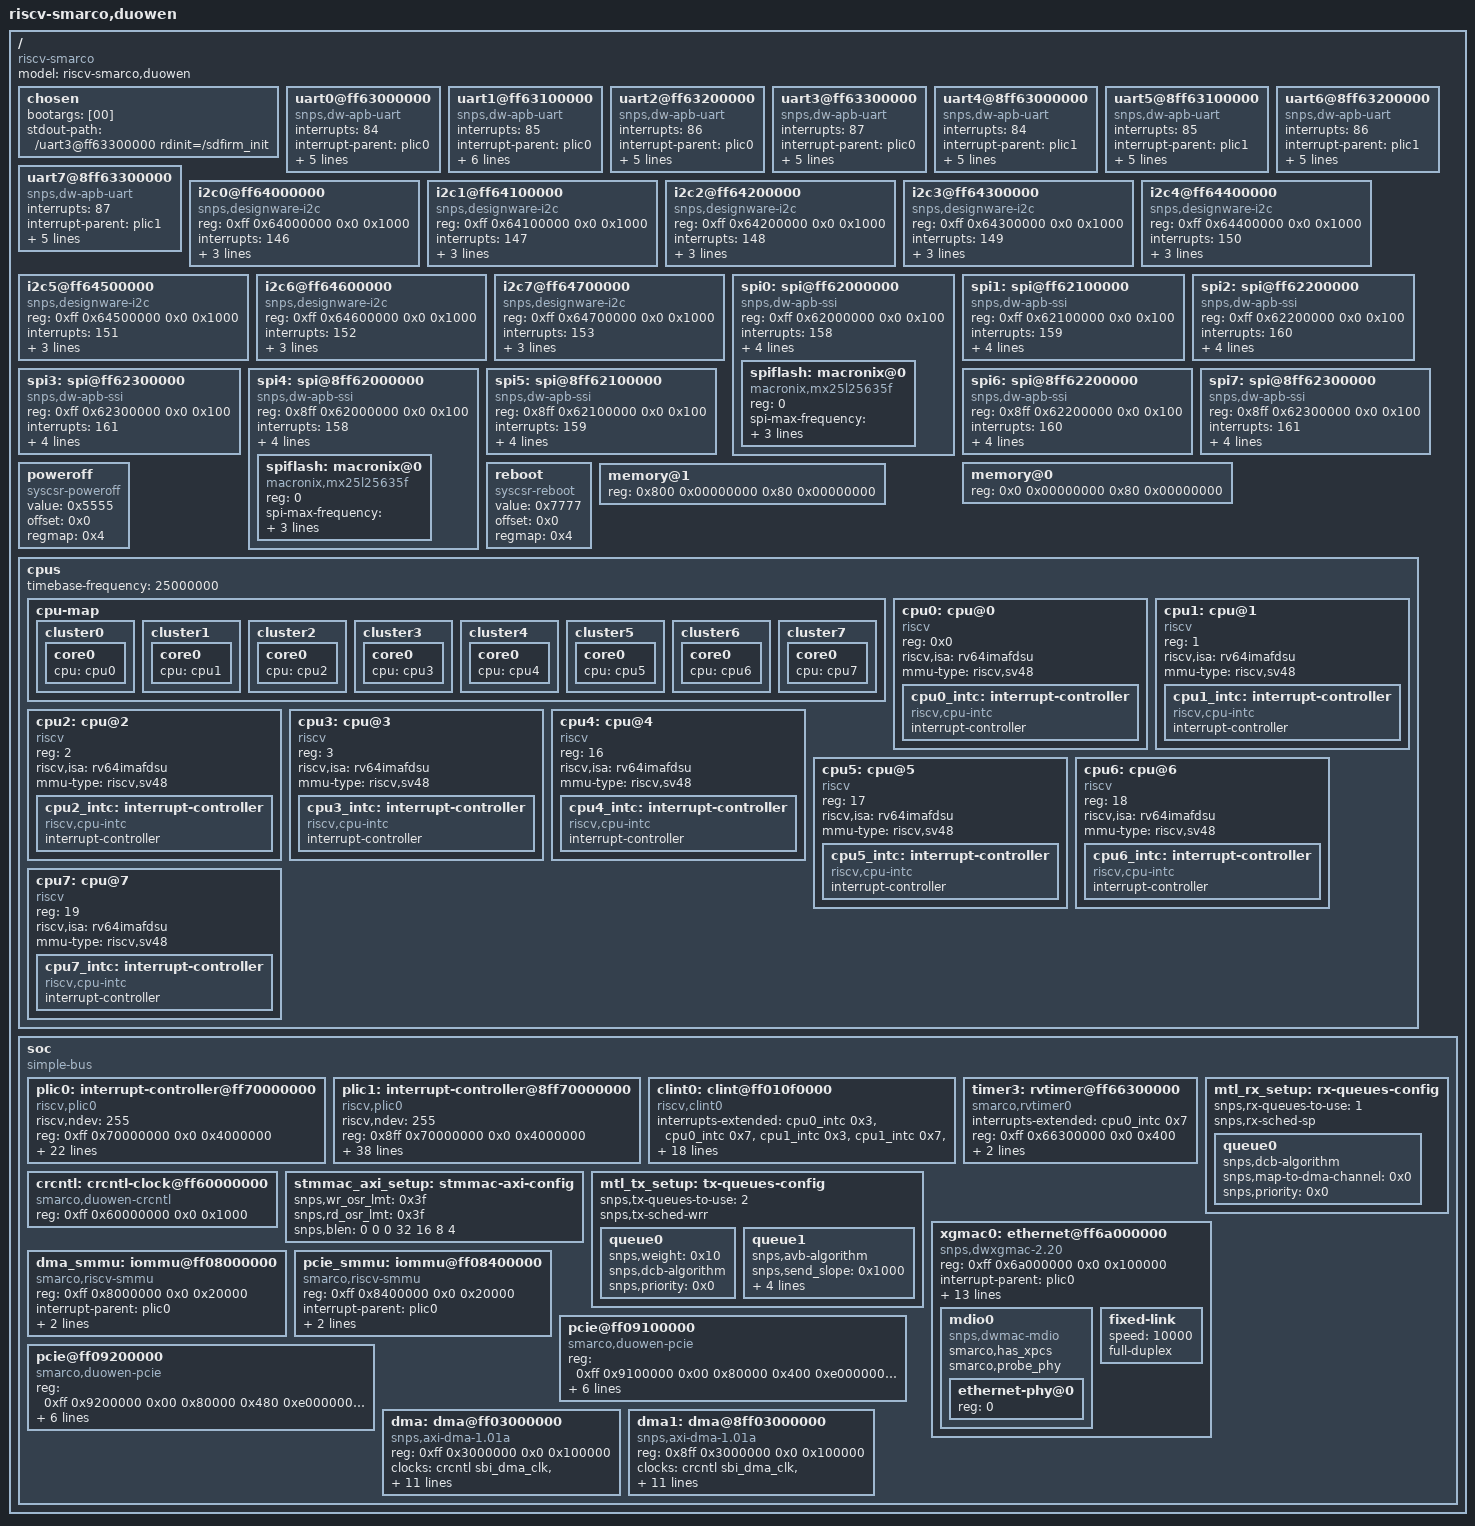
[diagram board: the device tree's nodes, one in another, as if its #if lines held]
/* SPDX-License-Identifier: GPL-2.0-or-later */
/*
 *  Copyright (C) 2021 CAS SmartCore Co., Ltd.
 *    Author: 2021 Lv Zheng <zhenglv@smarco.cn>
 */

#include <target/config.h>
#include <dt-bindings/clock/sbi-clock-duowen.h>

/dts-v1/;

/ {
	#address-cells = <0x2>;
	#size-cells = <0x2>;
	compatible = "riscv-smarco";
	model = "riscv-smarco,duowen";

	chosen {
#ifdef CONFIG_DUOWEN_UART_DTS_CON
		bootargs = [00];
#ifdef CONFIG_DUOWEN_UART_CON0
		stdout-path = "/uart0@ff63000000 rdinit=/sdfirm_init";
#endif /* CONFIG_DUOWEN_UART_CON0 */
#ifdef CONFIG_DUOWEN_UART_CON1
		stdout-path = "/uart1@ff63100000 rdinit=/sdfirm_init";
#endif /* CONFIG_DUOWEN_UART_CON1 */
#ifdef CONFIG_DUOWEN_UART_CON2
		stdout-path = "/uart2@ff63200000 rdinit=/sdfirm_init";
#endif /* CONFIG_DUOWEN_UART_CON2 */
#ifdef CONFIG_DUOWEN_UART_CON3
		stdout-path = "/uart3@ff63300000 rdinit=/sdfirm_init";
#endif /* CONFIG_DUOWEN_UART_CON3 */
#else /* CONFIG_DUOWEN_UART_DTS_CON */
		bootargs = "console=hvc0 earlycon=sbi rdinit=/sdfirm_init";
#endif /* CONFIG_DUOWEN_UART_DTS_CON */
	};

#ifdef CONFIG_DUOWEN_UART_DTS
	uart0@ff63000000 {
		interrupts = <84>;
		interrupt-parent = <&plic0>;
#ifdef CONFIG_DUOWEN_UART_DTS_CLK_FREQ
		clock-frequency = <APB_CLK_FREQ>;
#else
		clocks = <&crcntl sbi_uart0_clk>, <&crcntl sbi_uart0_clk>;
		clock-names = "baudclk", "apb_pclk";
#endif
		reg = <0xff 0x63000000 0x0 0x100>;
		reg-io-width = <4>;
		reg-shift = <2>;
		compatible = "snps,dw-apb-uart";
#ifdef CONFIG_DUOWEN_UART_CON0
#ifdef CONFIG_DUOWEN_UART_DTS_CON
		status = "okay";
		current-speed = <UART_CURRENT_SPEED>;
#else /* CONFIG_DUOWEN_UART_DTS_CON */
		status = "disabled";
#endif /* CONFIG_DUOWEN_UART_DTS_CON */
#else /* CONFIG_DUOWEN_UART_CON0 */
		status = "okay";
#endif /* CONFIG_DUOWEN_UART_CON0 */
	};
	uart1@ff63100000 {
		interrupts = <85>;
		interrupt-parent = <&plic0>;
#ifdef CONFIG_DUOWEN_UART_DTS_CLK_FREQ
		clock-frequency = <APB_CLK_FREQ>;
#else
		clocks = <&crcntl sbi_uart1_clk>, <&crcntl sbi_uart1_clk>;
		clock-names = "baudclk", "apb_pclk";
#endif
		reg = <0xff 0x63100000 0x0 0x100>;
		reg-io-width = <4>;
		reg-shift = <2>;
		compatible = "snps,dw-apb-uart";
#ifdef CONFIG_DUOWEN_UART_DTS_DMA
		dmas = <&dma 0>, <&dma 1>;
		dma-names = "tx", "rx";
#endif /* CONFIG_DUOWEN_UART_DTS_DMA */
#ifdef CONFIG_DUOWEN_UART_CON1
#ifdef CONFIG_DUOWEN_UART_DTS_CON
		status = "okay";
		current-speed = <UART_CURRENT_SPEED>;
#else /* CONFIG_DUOWEN_UART_DTS_CON */
		status = "disabled";
#endif /* CONFIG_DUOWEN_UART_DTS_CON */
#else /* CONFIG_DUOWEN_UART_CON1 */
		status = "okay";
#endif /* CONFIG_DUOWEN_UART_CON1 */
	};
	uart2@ff63200000 {
		interrupts = <86>;
		interrupt-parent = <&plic0>;
#ifdef CONFIG_DUOWEN_UART_DTS_CLK_FREQ
		clock-frequency = <APB_CLK_FREQ>;
#else /* CONFIG_DUOWEN_UART_DTS_CLK_FREQ */
		clocks = <&crcntl sbi_uart2_clk>, <&crcntl sbi_uart2_clk>;
		clock-names = "baudclk", "apb_pclk";
#endif /* CONFIG_DUOWEN_UART_DTS_CLK_FREQ */
		reg = <0xff 0x63200000 0x0 0x100>;
		reg-io-width = <4>;
		reg-shift = <2>;
		compatible = "snps,dw-apb-uart";
#ifdef CONFIG_DUOWEN_UART_CON2
#ifdef CONFIG_DUOWEN_UART_DTS_CON
		status = "okay";
		current-speed = <UART_CURRENT_SPEED>;
#else /* CONFIG_DUOWEN_UART_DTS_CON */
		status = "disabled";
#endif /* CONFIG_DUOWEN_UART_DTS_CON */
#else /* CONFIG_DUOWEN_UART_CON2 */
		status = "okay";
#endif /* CONFIG_DUOWEN_UART_CON2 */
	};
	uart3@ff63300000 {
		interrupts = <87>;
		interrupt-parent = <&plic0>;
#ifdef CONFIG_DUOWEN_UART_DTS_CLK_FREQ
		clock-frequency = <APB_CLK_FREQ>;
#else /* CONFIG_DUOWEN_UART_DTS_CLK_FREQ */
		clocks = <&crcntl sbi_uart3_clk>, <&crcntl sbi_uart3_clk>;
		clock-names = "baudclk", "apb_pclk";
#endif /* CONFIG_DUOWEN_UART_DTS_CLK_FREQ */
		reg = <0xff 0x63300000 0x0 0x100>;
		reg-io-width = <4>;
		reg-shift = <2>;
		compatible = "snps,dw-apb-uart";
#ifdef CONFIG_DUOWEN_UART_CON3
#ifdef CONFIG_DUOWEN_UART_DTS_CON
		status = "okay";
		current-speed = <UART_CURRENT_SPEED>;
#else /* CONFIG_DUOWEN_UART_DTS_CON */
		status = "disabled";
#endif /* CONFIG_DUOWEN_UART_DTS_CON */
#else /* CONFIG_DUOWEN_UART_CON3 */
		status = "okay";
#endif /* CONFIG_DUOWEN_UART_CON3 */
	};
#ifdef CONFIG_DUOWEN_SBI_DUAL
	uart4@8ff63000000 {
		interrupts = <84>;
		interrupt-parent = <&plic1>;
#ifdef CONFIG_DUOWEN_UART_DTS_CLK_FREQ
		clock-frequency = <APB_CLK_FREQ>;
#else /* CONFIG_DUOWEN_UART_DTS_CLK_FREQ */
		clocks = <&crcntl sbi_uart0_clk2>, <&crcntl sbi_uart0_clk2>;
		clock-names = "baudclk", "apb_pclk";
#endif /* CONFIG_DUOWEN_UART_DTS_CLK_FREQ */
		reg = <0x8ff 0x63000000 0x0 0x100>;
		reg-io-width = <4>;
		reg-shift = <2>;
		compatible = "snps,dw-apb-uart";
#ifdef CONFIG_DUOWEN_UART_CON4
#ifdef CONFIG_DUOWEN_UART_DTS_CON
		status = "okay";
		current-speed = <UART_CURRENT_SPEED>;
#else /* CONFIG_DUOWEN_UART_DTS_CON */
		status = "disabled";
#endif /* CONFIG_DUOWEN_UART_DTS_CON */
#else /* CONFIG_DUOWEN_UART_CON4 */
		status = "okay";
#endif /* CONFIG_DUOWEN_UART_CON4 */
	};
	uart5@8ff63100000 {
		interrupts = <85>;
		interrupt-parent = <&plic1>;
#ifdef CONFIG_DUOWEN_UART_DTS_CLK_FREQ
		clock-frequency = <APB_CLK_FREQ>;
#else /* CONFIG_DUOWEN_UART_DTS_CLK_FREQ */
		clocks = <&crcntl sbi_uart1_clk2>, <&crcntl sbi_uart1_clk2>;
		clock-names = "baudclk", "apb_pclk";
#endif /* CONFIG_DUOWEN_UART_DTS_CLK_FREQ */
		reg = <0x8ff 0x63100000 0x0 0x100>;
		reg-io-width = <4>;
		reg-shift = <2>;
		compatible = "snps,dw-apb-uart";
#ifdef CONFIG_DUOWEN_UART_CON5
#ifdef CONFIG_DUOWEN_UART_DTS_CON
		status = "okay";
		current-speed = <UART_CURRENT_SPEED>;
#else /* CONFIG_DUOWEN_UART_DTS_CON */
		status = "disabled";
#endif /* CONFIG_DUOWEN_UART_DTS_CON */
#else /* CONFIG_DUOWEN_UART_CON5 */
		status = "okay";
#endif /* CONFIG_DUOWEN_UART_CON5 */
	};
	uart6@8ff63200000 {
		interrupts = <86>;
		interrupt-parent = <&plic1>;
#ifdef CONFIG_DUOWEN_UART_DTS_CLK_FREQ
		clock-frequency = <APB_CLK_FREQ>;
#else /* CONFIG_DUOWEN_UART_DTS_CLK_FREQ */
		clocks = <&crcntl sbi_uart2_clk2>, <&crcntl sbi_uart2_clk2>;
		clock-names = "baudclk", "apb_pclk";
#endif /* CONFIG_DUOWEN_UART_DTS_CLK_FREQ */
		reg = <0x8ff 0x63200000 0x0 0x100>;
		reg-io-width = <4>;
		reg-shift = <2>;
		compatible = "snps,dw-apb-uart";
#ifdef CONFIG_DUOWEN_UART_CON6
#ifdef CONFIG_DUOWEN_UART_DTS_CON
		status = "okay";
		current-speed = <UART_CURRENT_SPEED>;
#else /* CONFIG_DUOWEN_UART_DTS_CON */
		status = "disabled";
#endif /* CONFIG_DUOWEN_UART_DTS_CON */
#else /* CONFIG_DUOWEN_UART_CON6 */
		status = "okay";
#endif /* CONFIG_DUOWEN_UART_CON6 */
	};
	uart7@8ff63300000 {
		interrupts = <87>;
		interrupt-parent = <&plic1>;
#ifdef CONFIG_DUOWEN_UART_DTS_CLK_FREQ
		clock-frequency = <APB_CLK_FREQ>;
#else /* CONFIG_DUOWEN_UART_DTS_CLK_FREQ */
		clocks = <&crcntl sbi_uart3_clk2>, <&crcntl sbi_uart3_clk2>;
		clock-names = "baudclk", "apb_pclk";
#endif /* CONFIG_DUOWEN_UART_DTS_CLK_FREQ */
		reg = <0x8ff 0x63300000 0x0 0x100>;
		reg-io-width = <4>;
		reg-shift = <2>;
		compatible = "snps,dw-apb-uart";
#ifdef CONFIG_DUOWEN_UART_CON7
#ifdef CONFIG_DUOWEN_UART_DTS_CON
		status = "okay";
		current-speed = <UART_CURRENT_SPEED>;
#else /* CONFIG_DUOWEN_UART_DTS_CON */
		status = "disabled";
#endif /* CONFIG_DUOWEN_UART_DTS_CON */
#else /* CONFIG_DUOWEN_UART_CON7 */
		status = "okay";
#endif /* CONFIG_DUOWEN_UART_CON7 */
	};
#endif /* CONFIG_DUOWEN_SBI_DUAL */
#endif /* CONFIG_DUOWEN_UART_DTS */

#ifdef CONFIG_DUOWEN_I2C_MASTER_DTS
	i2c0@ff64000000 {
		#address-cells = <1>;
		#size-cells = <0>;
		compatible = "snps,designware-i2c";
		reg = <0xff 0x64000000 0x0 0x1000>;
		interrupts = <146>;
		interrupt-parent = <&plic0>;
		clock-frequency = <I2C_MASTER_SPEED>;
		clocks = <&crcntl sbi_i2c0_clk>;
		clock-names = "pclk";
		status = "okay";
	};
	i2c1@ff64100000 {
		#address-cells = <1>;
		#size-cells = <0>;
		compatible = "snps,designware-i2c";
		reg = <0xff 0x64100000 0x0 0x1000>;
		interrupts = <147>;
		interrupt-parent = <&plic0>;
		clock-frequency = <I2C_MASTER_SPEED>;
		clocks = <&crcntl sbi_i2c1_clk>;
		clock-names = "pclk";
		status = "okay";
	};
	i2c2@ff64200000 {
		#address-cells = <1>;
		#size-cells = <0>;
		compatible = "snps,designware-i2c";
		reg = <0xff 0x64200000 0x0 0x1000>;
		interrupts = <148>;
		interrupt-parent = <&plic0>;
		clock-frequency = <I2C_MASTER_SPEED>;
		clocks = <&crcntl sbi_i2c2_clk>;
		clock-names = "pclk";
		status = "okay";
	};
	i2c3@ff64300000 {
		#address-cells = <1>;
		#size-cells = <0>;
		compatible = "snps,designware-i2c";
		reg = <0xff 0x64300000 0x0 0x1000>;
		interrupts = <149>;
		interrupt-parent = <&plic0>;
		clock-frequency = <I2C_MASTER_SPEED>;
		clocks = <&crcntl sbi_i2c3_clk>;
		clock-names = "pclk";
		status = "okay";
	};
	i2c4@ff64400000 {
		#address-cells = <1>;
		#size-cells = <0>;
		compatible = "snps,designware-i2c";
		reg = <0xff 0x64400000 0x0 0x1000>;
		interrupts = <150>;
		interrupt-parent = <&plic0>;
		clock-frequency = <I2C_MASTER_SPEED>;
		clocks = <&crcntl sbi_i2c4_clk>;
		clock-names = "pclk";
		status = "okay";
	};
	i2c5@ff64500000 {
		#address-cells = <1>;
		#size-cells = <0>;
		compatible = "snps,designware-i2c";
		reg = <0xff 0x64500000 0x0 0x1000>;
		interrupts = <151>;
		interrupt-parent = <&plic0>;
		clock-frequency = <I2C_MASTER_SPEED>;
		clocks = <&crcntl sbi_i2c5_clk>;
		clock-names = "pclk";
		status = "okay";
	};
	i2c6@ff64600000 {
		#address-cells = <1>;
		#size-cells = <0>;
		compatible = "snps,designware-i2c";
		reg = <0xff 0x64600000 0x0 0x1000>;
		interrupts = <152>;
		interrupt-parent = <&plic0>;
		clock-frequency = <I2C_MASTER_SPEED>;
		clocks = <&crcntl sbi_i2c6_clk>;
		clock-names = "pclk";
		status = "okay";
	};
	i2c7@ff64700000 {
		#address-cells = <1>;
		#size-cells = <0>;
		compatible = "snps,designware-i2c";
		reg = <0xff 0x64700000 0x0 0x1000>;
		interrupts = <153>;
		interrupt-parent = <&plic0>;
		clock-frequency = <I2C_MASTER_SPEED>;
		clocks = <&crcntl sbi_i2c7_clk>;
		clock-names = "pclk";
		status = "okay";
	};
#endif /* CONFIG_DUOWEN_I2C_MASTER_DTS */

#ifdef CONFIG_DUOWEN_SSI_MASTER_DTS
	spi0: spi@ff62000000 {
		#address-cells = <1>;
		#size-cells = <0>;
		compatible = "snps,dw-apb-ssi";
		reg = <0xff 0x62000000 0x0 0x100>;
		interrupts = <158>;
		interrupt-parent = <&plic0>;
		clocks = <&crcntl sbi_spi0_clk>;
		clock-names = "pclk";
		reg-io-width = <4>;
		num-cs = <1>;
		status = "okay";
#ifdef CONFIG_DUOWEN_SSI_FLASH_SPI0
		spiflash: macronix@0 {
			#address-cells = <1>;
			#size-cells = <1>;
			reg = <0>;
			compatible = "macronix,mx25l25635f", "jedec,spi-nor";
			spi-max-frequency = <CONFIG_DUOWEN_SSI_FLASH_FREQ>;
			spi-cpha;
			spi-cpol;
			status = "okay";
		};
#endif /* CONFIG_DUOWEN_SSI_FLASH_SPI0 */
	};
	spi1: spi@ff62100000 {
		#address-cells = <1>;
		#size-cells = <0>;
		compatible = "snps,dw-apb-ssi";
		reg = <0xff 0x62100000 0x0 0x100>;
		interrupts = <159>;
		interrupt-parent = <&plic0>;
		clocks = <&crcntl sbi_spi1_clk>;
		clock-names = "pclk";
		reg-io-width = <4>;
		num-cs = <1>;
		status = "okay";
	};
	spi2: spi@ff62200000 {
		#address-cells = <1>;
		#size-cells = <0>;
		compatible = "snps,dw-apb-ssi";
		reg = <0xff 0x62200000 0x0 0x100>;
		interrupts = <160>;
		interrupt-parent = <&plic0>;
		clocks = <&crcntl sbi_spi2_clk>;
		clock-names = "pclk";
		reg-io-width = <4>;
		num-cs = <1>;
		status = "okay";
	};
	spi3: spi@ff62300000 {
		#address-cells = <1>;
		#size-cells = <0>;
		compatible = "snps,dw-apb-ssi";
		reg = <0xff 0x62300000 0x0 0x100>;
		interrupts = <161>;
		interrupt-parent = <&plic0>;
		clocks = <&crcntl sbi_spi3_clk>;
		clock-names = "pclk";
		reg-io-width = <4>;
		num-cs = <1>;
		status = "okay";
	};
#ifdef CONFIG_DUOWEN_SBI_DUAL
	spi4: spi@8ff62000000 {
		#address-cells = <1>;
		#size-cells = <0>;
		compatible = "snps,dw-apb-ssi";
		reg = <0x8ff 0x62000000 0x0 0x100>;
		interrupts = <158>;
		interrupt-parent = <&plic1>;
		clocks = <&crcntl sbi_spi0_clk>;
		clock-names = "pclk";
		reg-io-width = <4>;
		num-cs = <1>;
		status = "okay";
#ifdef CONFIG_DUOWEN_SSI_FLASH_SPI0
		spiflash: macronix@0 {
			#address-cells = <1>;
			#size-cells = <1>;
			reg = <0>;
			compatible = "macronix,mx25l25635f", "jedec,spi-nor";
			spi-max-frequency = <CONFIG_DUOWEN_SSI_FLASH_FREQ>;
			spi-cpha;
			spi-cpol;
			status = "okay";
		};
#endif /* CONFIG_DUOWEN_SSI_FLASH_SPI0 */
	};
	spi5: spi@8ff62100000 {
		#address-cells = <1>;
		#size-cells = <0>;
		compatible = "snps,dw-apb-ssi";
		reg = <0x8ff 0x62100000 0x0 0x100>;
		interrupts = <159>;
		interrupt-parent = <&plic1>;
		clocks = <&crcntl sbi_spi1_clk>;
		clock-names = "pclk";
		reg-io-width = <4>;
		num-cs = <1>;
		status = "okay";
	};
	spi6: spi@8ff62200000 {
		#address-cells = <1>;
		#size-cells = <0>;
		compatible = "snps,dw-apb-ssi";
		reg = <0x8ff 0x62200000 0x0 0x100>;
		interrupts = <160>;
		interrupt-parent = <&plic1>;
		clocks = <&crcntl sbi_spi2_clk>;
		clock-names = "pclk";
		reg-io-width = <4>;
		num-cs = <1>;
		status = "okay";
	};
	spi7: spi@8ff62300000 {
		#address-cells = <1>;
		#size-cells = <0>;
		compatible = "snps,dw-apb-ssi";
		reg = <0x8ff 0x62300000 0x0 0x100>;
		interrupts = <161>;
		interrupt-parent = <&plic1>;
		clocks = <&crcntl sbi_spi3_clk>;
		clock-names = "pclk";
		reg-io-width = <4>;
		num-cs = <1>;
		status = "okay";
	};
#endif /* CONFIG_DUOWEN_SBI_DUAL */
#endif /* CONFIG_DUOWEN_SSI_MASTER_DTS */

	poweroff {
		value = <0x5555>;
		offset = <0x0>;
		regmap = <0x4>;
		compatible = "syscsr-poweroff";
	};

	reboot {
		value = <0x7777>;
		offset = <0x0>;
		regmap = <0x4>;
		compatible = "syscsr-reboot";
	};

#ifndef CONFIG_DUOWEN_DDR_DUAL_SOC1
	memory@0 {
		device_type = "memory";
#ifdef CONFIG_DUOWEN_DDR_32M
		reg = <0x0 0x00000000 0x0 0x02000000>;
#endif /* CONFIG_DUOWEN_DDR_32M */
#ifdef CONFIG_DUOWEN_DDR_64M
		reg = <0x0 0x00000000 0x0 0x04000000>;
#endif /* CONFIG_DUOWEN_DDR_64M */
#ifdef CONFIG_DUOWEN_DDR_128M
		reg = <0x0 0x00000000 0x0 0x08000000>;
#endif /* CONFIG_DUOWEN_DDR_128M */
#ifdef CONFIG_DUOWEN_DDR_256M
		reg = <0x0 0x00000000 0x0 0x10000000>;
#endif /* CONFIG_DUOWEN_DDR_256M */
#ifdef CONFIG_DUOWEN_DDR_512M
		reg = <0x0 0x00000000 0x0 0x20000000>;
#endif /* CONFIG_DUOWEN_DDR_512M */
#ifdef CONFIG_DUOWEN_DDR_1G
		reg = <0x0 0x00000000 0x0 0x40000000>;
#endif /* CONFIG_DUOWEN_DDR_1G */
#ifdef CONFIG_DUOWEN_DDR_2G
		reg = <0x0 0x00000000 0x0 0x80000000>;
#endif /* CONFIG_DUOWEN_DDR_2G */
#ifdef CONFIG_DUOWEN_DDR_4G
		reg = <0x0 0x00000000 0x1 0x00000000>;
#endif /* CONFIG_DUOWEN_DDR_4G */
#ifdef CONFIG_DUOWEN_DDR_8G
		reg = <0x0 0x00000000 0x2 0x00000000>;
#endif /* CONFIG_DUOWEN_DDR_8G */
#ifdef CONFIG_DUOWEN_DDR_16G
		reg = <0x0 0x00000000 0x4 0x00000000>;
#endif /* CONFIG_DUOWEN_DDR_16G */
#ifdef CONFIG_DUOWEN_DDR_32G
		reg = <0x0 0x00000000 0x8 0x00000000>;
#endif /* CONFIG_DUOWEN_DDR_32G */
#ifdef CONFIG_DUOWEN_DDR_64G
		reg = <0x0 0x00000000 0x10 0x00000000>;
#endif /* CONFIG_DUOWEN_DDR_64G */
#ifdef CONFIG_DUOWEN_DDR_128G
		reg = <0x0 0x00000000 0x20 0x00000000>;
#endif /* CONFIG_DUOWEN_DDR_128G */
#ifdef CONFIG_DUOWEN_DDR_256G
		reg = <0x0 0x00000000 0x40 0x00000000>;
#endif /* CONFIG_DUOWEN_DDR_256G */
#ifdef CONFIG_DUOWEN_DDR_512G
		reg = <0x0 0x00000000 0x80 0x00000000>;
#endif /* CONFIG_DUOWEN_DDR_512G */
	};
#endif /* CONFIG_DUOWEN_DDR_DUAL_SOC1 */

#ifdef CONFIG_DUOWEN_DDR_DUAL_SOC1
	memory@1 {
		device_type = "memory";
#ifdef CONFIG_DUOWEN_DDR_32M
		reg = <0x800 0x00000000 0x0 0x02000000>;
#endif /* CONFIG_DUOWEN_DDR_32M */
#ifdef CONFIG_DUOWEN_DDR_64M
		reg = <0x800 0x00000000 0x0 0x04000000>;
#endif /* CONFIG_DUOWEN_DDR_64M */
#ifdef CONFIG_DUOWEN_DDR_128M
		reg = <0x800 0x00000000 0x0 0x08000000>;
#endif /* CONFIG_DUOWEN_DDR_128M */
#ifdef CONFIG_DUOWEN_DDR_256M
		reg = <0x800 0x00000000 0x0 0x10000000>;
#endif /* CONFIG_DUOWEN_DDR_256M */
#ifdef CONFIG_DUOWEN_DDR_512M
		reg = <0x800 0x00000000 0x0 0x20000000>;
#endif /* CONFIG_DUOWEN_DDR_512M */
#ifdef CONFIG_DUOWEN_DDR_1G
		reg = <0x800 0x00000000 0x0 0x40000000>;
#endif /* CONFIG_DUOWEN_DDR_1G */
#ifdef CONFIG_DUOWEN_DDR_2G
		reg = <0x800 0x00000000 0x0 0x80000000>;
#endif /* CONFIG_DUOWEN_DDR_2G */
#ifdef CONFIG_DUOWEN_DDR_4G
		reg = <0x800 0x00000000 0x1 0x00000000>;
#endif /* CONFIG_DUOWEN_DDR_4G */
#ifdef CONFIG_DUOWEN_DDR_8G
		reg = <0x800 0x00000000 0x2 0x00000000>;
#endif /* CONFIG_DUOWEN_DDR_8G */
#ifdef CONFIG_DUOWEN_DDR_16G
		reg = <0x800 0x00000000 0x4 0x00000000>;
#endif /* CONFIG_DUOWEN_DDR_16G */
#ifdef CONFIG_DUOWEN_DDR_32G
		reg = <0x800 0x00000000 0x8 0x00000000>;
#endif /* CONFIG_DUOWEN_DDR_32G */
#ifdef CONFIG_DUOWEN_DDR_64G
		reg = <0x800 0x00000000 0x10 0x00000000>;
#endif /* CONFIG_DUOWEN_DDR_64G */
#ifdef CONFIG_DUOWEN_DDR_128G
		reg = <0x800 0x00000000 0x20 0x00000000>;
#endif /* CONFIG_DUOWEN_DDR_128G */
#ifdef CONFIG_DUOWEN_DDR_256G
		reg = <0x800 0x00000000 0x40 0x00000000>;
#endif /* CONFIG_DUOWEN_DDR_256G */
#ifdef CONFIG_DUOWEN_DDR_512G
		reg = <0x800 0x00000000 0x80 0x00000000>;
#endif /* CONFIG_DUOWEN_DDR_512G */
	};
#endif /* CONFIG_DUOWEN_DDR_DUAL_SOC1 */

	cpus {
		#address-cells = <0x1>;
		#size-cells = <0x0>;
		timebase-frequency = <25000000>;

#ifdef CONFIG_DUOWEN_APC
#ifdef CONFIG_SMP
#ifdef CONFIG_DUOWEN_APC_4
#ifdef CONFIG_DUOWEN_SBI_DUAL
		cpu-map {
			cluster0 {
				core0 {
					cpu = <&cpu0>;
				};
			};
			cluster1 {
				core0 {
					cpu = <&cpu1>;
				};
			};
			cluster2 {
				core0 {
					cpu = <&cpu2>;
				};
			};
			cluster3 {
				core0 {
					cpu = <&cpu3>;
				};
			};
			cluster4 {
				core0 {
					cpu = <&cpu4>;
				};
			};
			cluster5 {
				core0 {
					cpu = <&cpu5>;
				};
			};
			cluster6 {
				core0 {
					cpu = <&cpu6>;
				};
			};
			cluster7 {
				core0 {
					cpu = <&cpu7>;
				};
			};
		};
		cpu0: cpu@0 {
			device_type = "cpu";
			reg = <0>;
			status = "okay";
			compatible = "riscv";
			riscv,isa = "rv64imafdsu";
			mmu-type = "riscv,sv48";
			cpu0_intc: interrupt-controller {
				#interrupt-cells = <0x1>;
				interrupt-controller;
				compatible = "riscv,cpu-intc";
			};
		};
		cpu1: cpu@1 {
			device_type = "cpu";
			reg = <1>;
			status = "okay";
			compatible = "riscv";
			riscv,isa = "rv64imafdsu";
			mmu-type = "riscv,sv48";
			cpu1_intc: interrupt-controller {
				#interrupt-cells = <0x1>;
				interrupt-controller;
				compatible = "riscv,cpu-intc";
			};
		};
		cpu2: cpu@2 {
			device_type = "cpu";
			reg = <2>;
			status = "okay";
			compatible = "riscv";
			riscv,isa = "rv64imafdsu";
			mmu-type = "riscv,sv48";
			cpu2_intc: interrupt-controller {
				#interrupt-cells = <0x1>;
				interrupt-controller;
				compatible = "riscv,cpu-intc";
			};
		};
		cpu3: cpu@3 {
			device_type = "cpu";
			reg = <3>;
			status = "okay";
			compatible = "riscv";
			riscv,isa = "rv64imafdsu";
			mmu-type = "riscv,sv48";
			cpu3_intc: interrupt-controller {
				#interrupt-cells = <0x1>;
				interrupt-controller;
				compatible = "riscv,cpu-intc";
			};
		};
		cpu4: cpu@4 {
			device_type = "cpu";
			reg = <16>;
			status = "okay";
			compatible = "riscv";
			riscv,isa = "rv64imafdsu";
			mmu-type = "riscv,sv48";
			cpu4_intc: interrupt-controller {
				#interrupt-cells = <0x1>;
				interrupt-controller;
				compatible = "riscv,cpu-intc";
			};
		};
		cpu5: cpu@5 {
			device_type = "cpu";
			reg = <17>;
			status = "okay";
			compatible = "riscv";
			riscv,isa = "rv64imafdsu";
			mmu-type = "riscv,sv48";
			cpu5_intc: interrupt-controller {
				#interrupt-cells = <0x1>;
				interrupt-controller;
				compatible = "riscv,cpu-intc";
			};
		};
		cpu6: cpu@6 {
			device_type = "cpu";
			reg = <18>;
			status = "okay";
			compatible = "riscv";
			riscv,isa = "rv64imafdsu";
			mmu-type = "riscv,sv48";
			cpu6_intc: interrupt-controller {
				#interrupt-cells = <0x1>;
				interrupt-controller;
				compatible = "riscv,cpu-intc";
			};
		};
		cpu7: cpu@7 {
			device_type = "cpu";
			reg = <19>;
			status = "okay";
			compatible = "riscv";
			riscv,isa = "rv64imafdsu";
			mmu-type = "riscv,sv48";
			cpu7_intc: interrupt-controller {
				#interrupt-cells = <0x1>;
				interrupt-controller;
				compatible = "riscv,cpu-intc";
			};
		};
#else /* CONFIG_DUOWEN_SBI_DUAL */
		cpu-map {
			cluster0 {
				core0 {
					cpu = <&cpu0>;
				};
			};
			cluster1 {
				core0 {
					cpu = <&cpu1>;
				};
			};
			cluster2 {
				core0 {
					cpu = <&cpu2>;
				};
			};
			cluster3 {
				core0 {
					cpu = <&cpu3>;
				};
			};
		};
		cpu0: cpu@0 {
			device_type = "cpu";
			reg = <0>;
			status = "okay";
			compatible = "riscv";
			riscv,isa = "rv64imafdsu";
			mmu-type = "riscv,sv48";
			cpu0_intc: interrupt-controller {
				#interrupt-cells = <0x1>;
				interrupt-controller;
				compatible = "riscv,cpu-intc";
			};
		};
		cpu1: cpu@1 {
			device_type = "cpu";
			reg = <1>;
			status = "okay";
			compatible = "riscv";
			riscv,isa = "rv64imafdsu";
			mmu-type = "riscv,sv48";
			cpu1_intc: interrupt-controller {
				#interrupt-cells = <0x1>;
				interrupt-controller;
				compatible = "riscv,cpu-intc";
			};
		};
		cpu2: cpu@2 {
			device_type = "cpu";
			reg = <2>;
			status = "okay";
			compatible = "riscv";
			riscv,isa = "rv64imafdsu";
			mmu-type = "riscv,sv48";
			cpu2_intc: interrupt-controller {
				#interrupt-cells = <0x1>;
				interrupt-controller;
				compatible = "riscv,cpu-intc";
			};
		};
		cpu3: cpu@3 {
			device_type = "cpu";
			reg = <3>;
			status = "okay";
			compatible = "riscv";
			riscv,isa = "rv64imafdsu";
			mmu-type = "riscv,sv48";
			cpu3_intc: interrupt-controller {
				#interrupt-cells = <0x1>;
				interrupt-controller;
				compatible = "riscv,cpu-intc";
			};
		};
#endif /* CONFIG_DUOWEN_SBI_DUAL */
#else /* CONFIG_DUOWEN_APC_4 */
#ifdef CONFIG_DUOWEN_SBI_DUAL
		cpu-map {
			cluster0 {
				core0 {
					cpu = <&cpu0>;
				};
				core1 {
					cpu = <&cpu1>;
				};
				core2 {
					cpu = <&cpu2>;
				};
				core3 {
					cpu = <&cpu3>;
				};
			};
			cluster1 {
				core0 {
					cpu = <&cpu4>;
				};
				core1 {
					cpu = <&cpu5>;
				};
				core2 {
					cpu = <&cpu6>;
				};
				core3 {
					cpu = <&cpu7>;
				};
			};
			cluster2 {
				core0 {
					cpu = <&cpu8>;
				};
				core1 {
					cpu = <&cpu9>;
				};
				core2 {
					cpu = <&cpu10>;
				};
				core3 {
					cpu = <&cpu11>;
				};
			};
			cluster3 {
				core0 {
					cpu = <&cpu12>;
				};
				core1 {
					cpu = <&cpu13>;
				};
				core2 {
					cpu = <&cpu14>;
				};
				core3 {
					cpu = <&cpu15>;
				};
			};
			cluster4 {
				core0 {
					cpu = <&cpu16>;
				};
				core1 {
					cpu = <&cpu17>;
				};
				core2 {
					cpu = <&cpu18>;
				};
				core3 {
					cpu = <&cpu19>;
				};
			};
			cluster5 {
				core0 {
					cpu = <&cpu20>;
				};
				core1 {
					cpu = <&cpu21>;
				};
				core2 {
					cpu = <&cpu22>;
				};
				core3 {
					cpu = <&cpu23>;
				};
			};
			cluster6 {
				core0 {
					cpu = <&cpu24>;
				};
				core1 {
					cpu = <&cpu25>;
				};
				core2 {
					cpu = <&cpu26>;
				};
				core3 {
					cpu = <&cpu27>;
				};
			};
			cluster7 {
				core0 {
					cpu = <&cpu28>;
				};
				core1 {
					cpu = <&cpu29>;
				};
				core2 {
					cpu = <&cpu30>;
				};
				core3 {
					cpu = <&cpu31>;
				};
			};
		};
		cpu0: cpu@0 {
			device_type = "cpu";
			reg = <0>;
			status = "okay";
			compatible = "riscv";
			riscv,isa = "rv64imafdsu";
			mmu-type = "riscv,sv48";
			cpu0_intc: interrupt-controller {
				#interrupt-cells = <0x1>;
				interrupt-controller;
				compatible = "riscv,cpu-intc";
			};
		};
		cpu1: cpu@1 {
			device_type = "cpu";
			reg = <1>;
			status = "okay";
			compatible = "riscv";
			riscv,isa = "rv64imafdsu";
			mmu-type = "riscv,sv48";
			cpu1_intc: interrupt-controller {
				#interrupt-cells = <0x1>;
				interrupt-controller;
				compatible = "riscv,cpu-intc";
			};
		};
		cpu2: cpu@2 {
			device_type = "cpu";
			reg = <2>;
			status = "okay";
			compatible = "riscv";
			riscv,isa = "rv64imafdsu";
			mmu-type = "riscv,sv48";
			cpu2_intc: interrupt-controller {
				#interrupt-cells = <0x1>;
				interrupt-controller;
				compatible = "riscv,cpu-intc";
			};
		};
		cpu3: cpu@3 {
			device_type = "cpu";
			reg = <3>;
			status = "okay";
			compatible = "riscv";
			riscv,isa = "rv64imafdsu";
			mmu-type = "riscv,sv48";
			cpu3_intc: interrupt-controller {
				#interrupt-cells = <0x1>;
				interrupt-controller;
				compatible = "riscv,cpu-intc";
			};
		};
		cpu4: cpu@4 {
			device_type = "cpu";
			reg = <4>;
			status = "okay";
			compatible = "riscv";
			riscv,isa = "rv64imafdsu";
			mmu-type = "riscv,sv48";
			cpu4_intc: interrupt-controller {
				#interrupt-cells = <0x1>;
				interrupt-controller;
				compatible = "riscv,cpu-intc";
			};
		};
		cpu5: cpu@5 {
			device_type = "cpu";
			reg = <5>;
			status = "okay";
			compatible = "riscv";
			riscv,isa = "rv64imafdsu";
			mmu-type = "riscv,sv48";
			cpu5_intc: interrupt-controller {
				#interrupt-cells = <0x1>;
				interrupt-controller;
				compatible = "riscv,cpu-intc";
			};
		};
		cpu6: cpu@6 {
			device_type = "cpu";
			reg = <6>;
			status = "okay";
			compatible = "riscv";
			riscv,isa = "rv64imafdsu";
			mmu-type = "riscv,sv48";
			cpu6_intc: interrupt-controller {
				#interrupt-cells = <0x1>;
				interrupt-controller;
				compatible = "riscv,cpu-intc";
			};
		};
		cpu7: cpu@7 {
			device_type = "cpu";
			reg = <7>;
			status = "okay";
			compatible = "riscv";
			riscv,isa = "rv64imafdsu";
			mmu-type = "riscv,sv48";
			cpu7_intc: interrupt-controller {
				#interrupt-cells = <0x1>;
				interrupt-controller;
				compatible = "riscv,cpu-intc";
			};
		};
		cpu8: cpu@8 {
			device_type = "cpu";
			reg = <8>;
			status = "okay";
			compatible = "riscv";
			riscv,isa = "rv64imafdsu";
			mmu-type = "riscv,sv48";
			cpu8_intc: interrupt-controller {
				#interrupt-cells = <0x1>;
				interrupt-controller;
				compatible = "riscv,cpu-intc";
			};
		};
		cpu9: cpu@9 {
			device_type = "cpu";
			reg = <9>;
			status = "okay";
			compatible = "riscv";
			riscv,isa = "rv64imafdsu";
			mmu-type = "riscv,sv48";
			cpu9_intc: interrupt-controller {
				#interrupt-cells = <0x1>;
				interrupt-controller;
				compatible = "riscv,cpu-intc";
			};
		};
		cpu10: cpu@10 {
			device_type = "cpu";
			reg = <10>;
			status = "okay";
			compatible = "riscv";
			riscv,isa = "rv64imafdsu";
			mmu-type = "riscv,sv48";
			cpu10_intc: interrupt-controller {
				#interrupt-cells = <0x1>;
				interrupt-controller;
				compatible = "riscv,cpu-intc";
			};
		};
		cpu11: cpu@11 {
			device_type = "cpu";
			reg = <11>;
			status = "okay";
			compatible = "riscv";
			riscv,isa = "rv64imafdsu";
			mmu-type = "riscv,sv48";
			cpu11_intc: interrupt-controller {
				#interrupt-cells = <0x1>;
				interrupt-controller;
				compatible = "riscv,cpu-intc";
			};
		};
		cpu12: cpu@12 {
			device_type = "cpu";
			reg = <12>;
			status = "okay";
			compatible = "riscv";
			riscv,isa = "rv64imafdsu";
			mmu-type = "riscv,sv48";
			cpu12_intc: interrupt-controller {
				#interrupt-cells = <0x1>;
				interrupt-controller;
				compatible = "riscv,cpu-intc";
			};
		};
		cpu13: cpu@13 {
			device_type = "cpu";
			reg = <13>;
			status = "okay";
			compatible = "riscv";
			riscv,isa = "rv64imafdsu";
			mmu-type = "riscv,sv48";
			cpu13_intc: interrupt-controller {
				#interrupt-cells = <0x1>;
				interrupt-controller;
				compatible = "riscv,cpu-intc";
			};
		};
		cpu14: cpu@14 {
			device_type = "cpu";
			reg = <14>;
			status = "okay";
			compatible = "riscv";
			riscv,isa = "rv64imafdsu";
			mmu-type = "riscv,sv48";
			cpu14_intc: interrupt-controller {
				#interrupt-cells = <0x1>;
				interrupt-controller;
				compatible = "riscv,cpu-intc";
			};
		};
		cpu15: cpu@15 {
			device_type = "cpu";
			reg = <15>;
			status = "okay";
			compatible = "riscv";
			riscv,isa = "rv64imafdsu";
			mmu-type = "riscv,sv48";
			cpu15_intc: interrupt-controller {
				#interrupt-cells = <0x1>;
				interrupt-controller;
				compatible = "riscv,cpu-intc";
			};
		};
		cpu16: cpu@16 {
			device_type = "cpu";
			reg = <16>;
			status = "okay";
			compatible = "riscv";
			riscv,isa = "rv64imafdsu";
			mmu-type = "riscv,sv48";
			cpu16_intc: interrupt-controller {
				#interrupt-cells = <0x1>;
				interrupt-controller;
				compatible = "riscv,cpu-intc";
			};
		};
		cpu17: cpu@17 {
			device_type = "cpu";
			reg = <17>;
			status = "okay";
			compatible = "riscv";
			riscv,isa = "rv64imafdsu";
			mmu-type = "riscv,sv48";
			cpu17_intc: interrupt-controller {
				#interrupt-cells = <0x1>;
				interrupt-controller;
				compatible = "riscv,cpu-intc";
			};
		};
		cpu18: cpu@18 {
			device_type = "cpu";
			reg = <18>;
			status = "okay";
			compatible = "riscv";
			riscv,isa = "rv64imafdsu";
			mmu-type = "riscv,sv48";
			cpu18_intc: interrupt-controller {
				#interrupt-cells = <0x1>;
				interrupt-controller;
				compatible = "riscv,cpu-intc";
			};
		};
		cpu19: cpu@19 {
			device_type = "cpu";
			reg = <19>;
			status = "okay";
			compatible = "riscv";
			riscv,isa = "rv64imafdsu";
			mmu-type = "riscv,sv48";
			cpu19_intc: interrupt-controller {
				#interrupt-cells = <0x1>;
				interrupt-controller;
				compatible = "riscv,cpu-intc";
			};
		};
		cpu20: cpu@20 {
			device_type = "cpu";
			reg = <20>;
			status = "okay";
			compatible = "riscv";
			riscv,isa = "rv64imafdsu";
			mmu-type = "riscv,sv48";
			cpu20_intc: interrupt-controller {
				#interrupt-cells = <0x1>;
				interrupt-controller;
				compatible = "riscv,cpu-intc";
			};
		};
		cpu21: cpu@21 {
			device_type = "cpu";
			reg = <21>;
			status = "okay";
			compatible = "riscv";
			riscv,isa = "rv64imafdsu";
			mmu-type = "riscv,sv48";
			cpu21_intc: interrupt-controller {
				#interrupt-cells = <0x1>;
				interrupt-controller;
				compatible = "riscv,cpu-intc";
			};
		};
		cpu22: cpu@22 {
			device_type = "cpu";
			reg = <22>;
			status = "okay";
			compatible = "riscv";
			riscv,isa = "rv64imafdsu";
			mmu-type = "riscv,sv48";
			cpu22_intc: interrupt-controller {
				#interrupt-cells = <0x1>;
				interrupt-controller;
				compatible = "riscv,cpu-intc";
			};
		};
		cpu23: cpu@23 {
			device_type = "cpu";
			reg = <23>;
			status = "okay";
			compatible = "riscv";
			riscv,isa = "rv64imafdsu";
			mmu-type = "riscv,sv48";
			cpu23_intc: interrupt-controller {
				#interrupt-cells = <0x1>;
				interrupt-controller;
				compatible = "riscv,cpu-intc";
			};
		};
		cpu24: cpu@24 {
			device_type = "cpu";
			reg = <24>;
			status = "okay";
			compatible = "riscv";
			riscv,isa = "rv64imafdsu";
			mmu-type = "riscv,sv48";
			cpu24_intc: interrupt-controller {
				#interrupt-cells = <0x1>;
				interrupt-controller;
				compatible = "riscv,cpu-intc";
			};
		};
		cpu25: cpu@25 {
			device_type = "cpu";
			reg = <25>;
			status = "okay";
			compatible = "riscv";
			riscv,isa = "rv64imafdsu";
			mmu-type = "riscv,sv48";
			cpu25_intc: interrupt-controller {
				#interrupt-cells = <0x1>;
				interrupt-controller;
				compatible = "riscv,cpu-intc";
			};
		};
		cpu26: cpu@26 {
			device_type = "cpu";
			reg = <26>;
			status = "okay";
			compatible = "riscv";
			riscv,isa = "rv64imafdsu";
			mmu-type = "riscv,sv48";
			cpu26_intc: interrupt-controller {
				#interrupt-cells = <0x1>;
				interrupt-controller;
				compatible = "riscv,cpu-intc";
			};
		};
		cpu27: cpu@27 {
			device_type = "cpu";
			reg = <27>;
			status = "okay";
			compatible = "riscv";
			riscv,isa = "rv64imafdsu";
			mmu-type = "riscv,sv48";
			cpu27_intc: interrupt-controller {
				#interrupt-cells = <0x1>;
				interrupt-controller;
				compatible = "riscv,cpu-intc";
			};
		};
		cpu28: cpu@28 {
			device_type = "cpu";
			reg = <28>;
			status = "okay";
			compatible = "riscv";
			riscv,isa = "rv64imafdsu";
			mmu-type = "riscv,sv48";
			cpu28_intc: interrupt-controller {
				#interrupt-cells = <0x1>;
				interrupt-controller;
				compatible = "riscv,cpu-intc";
			};
		};
		cpu29: cpu@29 {
			device_type = "cpu";
			reg = <29>;
			status = "okay";
			compatible = "riscv";
			riscv,isa = "rv64imafdsu";
			mmu-type = "riscv,sv48";
			cpu29_intc: interrupt-controller {
				#interrupt-cells = <0x1>;
				interrupt-controller;
				compatible = "riscv,cpu-intc";
			};
		};
		cpu30: cpu@30 {
			device_type = "cpu";
			reg = <30>;
			status = "okay";
			compatible = "riscv";
			riscv,isa = "rv64imafdsu";
			mmu-type = "riscv,sv48";
			cpu30_intc: interrupt-controller {
				#interrupt-cells = <0x1>;
				interrupt-controller;
				compatible = "riscv,cpu-intc";
			};
		};
		cpu31: cpu@31 {
			device_type = "cpu";
			reg = <31>;
			status = "okay";
			compatible = "riscv";
			riscv,isa = "rv64imafdsu";
			mmu-type = "riscv,sv48";
			cpu31_intc: interrupt-controller {
				#interrupt-cells = <0x1>;
				interrupt-controller;
				compatible = "riscv,cpu-intc";
			};
		};
#else /* CONFIG_DUOWEN_SBI_DUAL */
		cpu-map {
			cluster0 {
				core0 {
					cpu = <&cpu0>;
				};
				core1 {
					cpu = <&cpu1>;
				};
				core2 {
					cpu = <&cpu2>;
				};
				core3 {
					cpu = <&cpu3>;
				};
			};
			cluster1 {
				core0 {
					cpu = <&cpu4>;
				};
				core1 {
					cpu = <&cpu5>;
				};
				core2 {
					cpu = <&cpu6>;
				};
				core3 {
					cpu = <&cpu7>;
				};
			};
			cluster2 {
				core0 {
					cpu = <&cpu8>;
				};
				core1 {
					cpu = <&cpu9>;
				};
				core2 {
					cpu = <&cpu10>;
				};
				core3 {
					cpu = <&cpu11>;
				};
			};
			cluster3 {
				core0 {
					cpu = <&cpu12>;
				};
				core1 {
					cpu = <&cpu13>;
				};
				core2 {
					cpu = <&cpu14>;
				};
				core3 {
					cpu = <&cpu15>;
				};
			};
		};
		cpu0: cpu@0 {
			device_type = "cpu";
			reg = <0>;
			status = "okay";
			compatible = "riscv";
			riscv,isa = "rv64imafdsu";
			mmu-type = "riscv,sv48";
			cpu0_intc: interrupt-controller {
				#interrupt-cells = <0x1>;
				interrupt-controller;
				compatible = "riscv,cpu-intc";
			};
		};
		cpu1: cpu@1 {
			device_type = "cpu";
			reg = <1>;
			status = "okay";
			compatible = "riscv";
			riscv,isa = "rv64imafdsu";
			mmu-type = "riscv,sv48";
			cpu1_intc: interrupt-controller {
				#interrupt-cells = <0x1>;
				interrupt-controller;
				compatible = "riscv,cpu-intc";
			};
		};
		cpu2: cpu@2 {
			device_type = "cpu";
			reg = <2>;
			status = "okay";
			compatible = "riscv";
			riscv,isa = "rv64imafdsu";
			mmu-type = "riscv,sv48";
			cpu2_intc: interrupt-controller {
				#interrupt-cells = <0x1>;
				interrupt-controller;
				compatible = "riscv,cpu-intc";
			};
		};
		cpu3: cpu@3 {
			device_type = "cpu";
			reg = <3>;
			status = "okay";
			compatible = "riscv";
			riscv,isa = "rv64imafdsu";
			mmu-type = "riscv,sv48";
			cpu3_intc: interrupt-controller {
				#interrupt-cells = <0x1>;
				interrupt-controller;
				compatible = "riscv,cpu-intc";
			};
		};
		cpu4: cpu@4 {
			device_type = "cpu";
			reg = <4>;
			status = "okay";
			compatible = "riscv";
			riscv,isa = "rv64imafdsu";
			mmu-type = "riscv,sv48";
			cpu4_intc: interrupt-controller {
				#interrupt-cells = <0x1>;
				interrupt-controller;
				compatible = "riscv,cpu-intc";
			};
		};
		cpu5: cpu@5 {
			device_type = "cpu";
			reg = <5>;
			status = "okay";
			compatible = "riscv";
			riscv,isa = "rv64imafdsu";
			mmu-type = "riscv,sv48";
			cpu5_intc: interrupt-controller {
				#interrupt-cells = <0x1>;
				interrupt-controller;
				compatible = "riscv,cpu-intc";
			};
		};
		cpu6: cpu@6 {
			device_type = "cpu";
			reg = <6>;
			status = "okay";
			compatible = "riscv";
			riscv,isa = "rv64imafdsu";
			mmu-type = "riscv,sv48";
			cpu6_intc: interrupt-controller {
				#interrupt-cells = <0x1>;
				interrupt-controller;
				compatible = "riscv,cpu-intc";
			};
		};
		cpu7: cpu@7 {
			device_type = "cpu";
			reg = <7>;
			status = "okay";
			compatible = "riscv";
			riscv,isa = "rv64imafdsu";
			mmu-type = "riscv,sv48";
			cpu7_intc: interrupt-controller {
				#interrupt-cells = <0x1>;
				interrupt-controller;
				compatible = "riscv,cpu-intc";
			};
		};
		cpu8: cpu@8 {
			device_type = "cpu";
			reg = <8>;
			status = "okay";
			compatible = "riscv";
			riscv,isa = "rv64imafdsu";
			mmu-type = "riscv,sv48";
			cpu8_intc: interrupt-controller {
				#interrupt-cells = <0x1>;
				interrupt-controller;
				compatible = "riscv,cpu-intc";
			};
		};
		cpu9: cpu@9 {
			device_type = "cpu";
			reg = <9>;
			status = "okay";
			compatible = "riscv";
			riscv,isa = "rv64imafdsu";
			mmu-type = "riscv,sv48";
			cpu9_intc: interrupt-controller {
				#interrupt-cells = <0x1>;
				interrupt-controller;
				compatible = "riscv,cpu-intc";
			};
		};
		cpu10: cpu@10 {
			device_type = "cpu";
			reg = <10>;
			status = "okay";
			compatible = "riscv";
			riscv,isa = "rv64imafdsu";
			mmu-type = "riscv,sv48";
			cpu10_intc: interrupt-controller {
				#interrupt-cells = <0x1>;
				interrupt-controller;
				compatible = "riscv,cpu-intc";
			};
		};
		cpu11: cpu@11 {
			device_type = "cpu";
			reg = <11>;
			status = "okay";
			compatible = "riscv";
			riscv,isa = "rv64imafdsu";
			mmu-type = "riscv,sv48";
			cpu11_intc: interrupt-controller {
				#interrupt-cells = <0x1>;
				interrupt-controller;
				compatible = "riscv,cpu-intc";
			};
		};
		cpu12: cpu@12 {
			device_type = "cpu";
			reg = <12>;
			status = "okay";
			compatible = "riscv";
			riscv,isa = "rv64imafdsu";
			mmu-type = "riscv,sv48";
			cpu12_intc: interrupt-controller {
				#interrupt-cells = <0x1>;
				interrupt-controller;
				compatible = "riscv,cpu-intc";
			};
		};
		cpu13: cpu@13 {
			device_type = "cpu";
			reg = <13>;
			status = "okay";
			compatible = "riscv";
			riscv,isa = "rv64imafdsu";
			mmu-type = "riscv,sv48";
			cpu13_intc: interrupt-controller {
				#interrupt-cells = <0x1>;
				interrupt-controller;
				compatible = "riscv,cpu-intc";
			};
		};
		cpu14: cpu@14 {
			device_type = "cpu";
			reg = <14>;
			status = "okay";
			compatible = "riscv";
			riscv,isa = "rv64imafdsu";
			mmu-type = "riscv,sv48";
			cpu14_intc: interrupt-controller {
				#interrupt-cells = <0x1>;
				interrupt-controller;
				compatible = "riscv,cpu-intc";
			};
		};
		cpu15: cpu@15 {
			device_type = "cpu";
			reg = <15>;
			status = "okay";
			compatible = "riscv";
			riscv,isa = "rv64imafdsu";
			mmu-type = "riscv,sv48";
			cpu15_intc: interrupt-controller {
				#interrupt-cells = <0x1>;
				interrupt-controller;
				compatible = "riscv,cpu-intc";
			};
		};
#endif /* CONFIG_DUOWEN_SBI_DUAL */
#endif /* CONFIG_DUOWEN_APC_4 */
#else /* CONFIG_SMP */
		cpu-map {
			cluster0 {
				core0 {
					cpu = <&cpu0>;
				};
			};
		};
		cpu0: cpu@0 {
			device_type = "cpu";
			reg = <0x0>;
			status = "okay";
			compatible = "riscv";
			riscv,isa = "rv64imafdsu";
			mmu-type = "riscv,sv48";
			cpu0_intc: interrupt-controller {
				#interrupt-cells = <0x1>;
				interrupt-controller;
				compatible = "riscv,cpu-intc";
			};
		};
#endif /* CONFIG_SMP */
#endif /* CONFIG_DUOWEN_APC */
#ifdef CONFIG_DUOWEN_IMC
		cpu-map {
			cluster0 {
				core0 {
					cpu = <&cpu0>;
				};
			};
		};
		cpu0: cpu@0 {
			device_type = "cpu";
			reg = <0x0>;
			status = "okay";
			compatible = "riscv";
			riscv,isa = "rv64imafdsu";
			mmu-type = "riscv,sv48";
			cpu0_intc: interrupt-controller {
				#interrupt-cells = <0x1>;
				interrupt-controller;
				compatible = "riscv,cpu-intc";
			};
		};
#endif /* CONFIG_DUOWEN_IMC */
	};

	soc {
		#address-cells = <0x2>;
		#size-cells = <0x2>;
		compatible = "simple-bus";
		ranges;

#ifdef CONFIG_DUOWEN_APC
		plic0: interrupt-controller@ff70000000 {
			riscv,ndev = <255>;
			reg = <0xff 0x70000000 0x0 0x4000000>;
			interrupts-extended = <
#ifdef CONFIG_SMP
#ifdef CONFIG_DUOWEN_APC_4
				&cpu0_intc  0xb        &cpu1_intc  0xb
				&cpu2_intc  0xb        &cpu3_intc  0xb
				&cpu0_intc  0xffffffff &cpu0_intc  0xffffffff
				&cpu0_intc  0xffffffff &cpu0_intc  0xffffffff
				&cpu0_intc  0xffffffff &cpu0_intc  0xffffffff
				&cpu0_intc  0xffffffff &cpu0_intc  0xffffffff
				&cpu0_intc  0xffffffff &cpu0_intc  0xffffffff
				&cpu0_intc  0xffffffff &cpu0_intc  0xffffffff
				&cpu0_intc  0xffffffff
				&cpu0_intc  0x9        &cpu1_intc  0x9
				&cpu2_intc  0x9        &cpu3_intc  0x9
				&cpu0_intc  0xffffffff &cpu0_intc  0xffffffff
				&cpu0_intc  0xffffffff &cpu0_intc  0xffffffff
				&cpu0_intc  0xffffffff &cpu0_intc  0xffffffff
				&cpu0_intc  0xffffffff &cpu0_intc  0xffffffff
				&cpu0_intc  0xffffffff &cpu0_intc  0xffffffff
				&cpu0_intc  0xffffffff &cpu0_intc  0xffffffff
				&cpu0_intc  0xffffffff
#ifdef CONFIG_DUOWEN_PLIC_DUAL
				&cpu0_intc  0xffffffff &cpu0_intc  0xffffffff
				&cpu0_intc  0xffffffff &cpu0_intc  0xffffffff
				&cpu0_intc  0xffffffff &cpu0_intc  0xffffffff
				&cpu0_intc  0xffffffff &cpu0_intc  0xffffffff
				&cpu0_intc  0xffffffff &cpu0_intc  0xffffffff
				&cpu0_intc  0xffffffff &cpu0_intc  0xffffffff
				&cpu0_intc  0xffffffff &cpu0_intc  0xffffffff
				&cpu0_intc  0xffffffff &cpu0_intc  0xffffffff
				&cpu0_intc  0xffffffff
				&cpu0_intc  0xffffffff &cpu0_intc  0xffffffff
				&cpu0_intc  0xffffffff &cpu0_intc  0xffffffff
				&cpu0_intc  0xffffffff &cpu0_intc  0xffffffff
				&cpu0_intc  0xffffffff &cpu0_intc  0xffffffff
				&cpu0_intc  0xffffffff &cpu0_intc  0xffffffff
				&cpu0_intc  0xffffffff &cpu0_intc  0xffffffff
				&cpu0_intc  0xffffffff &cpu0_intc  0xffffffff
				&cpu0_intc  0xffffffff &cpu0_intc  0xffffffff
				&cpu0_intc  0xffffffff
#endif /* CONFIG_DUOWEN_PLIC_DUAL */
#else /* CONFIG_DUOWEN_APC_4 */
				&cpu0_intc  0xb        &cpu1_intc  0xb
				&cpu2_intc  0xb        &cpu3_intc  0xb
				&cpu4_intc  0xb        &cpu5_intc  0xb
				&cpu6_intc  0xb        &cpu7_intc  0xb
				&cpu8_intc  0xb        &cpu9_intc  0xb
				&cpu10_intc 0xb        &cpu11_intc 0xb
				&cpu12_intc 0xb        &cpu13_intc 0xb
				&cpu14_intc 0xb        &cpu15_intc 0xb
				&cpu0_intc  0xffffffff
				&cpu0_intc  0x9        &cpu1_intc  0x9
				&cpu2_intc  0x9        &cpu3_intc  0x9
				&cpu4_intc  0x9        &cpu5_intc  0x9
				&cpu6_intc  0x9        &cpu7_intc  0x9
				&cpu8_intc  0x9        &cpu9_intc  0x9
				&cpu10_intc 0x9        &cpu11_intc 0x9
				&cpu12_intc 0x9        &cpu13_intc 0x9
				&cpu14_intc 0x9        &cpu15_intc 0x9
				&cpu0_intc  0xffffffff
#ifdef CONFIG_DUOWEN_PLIC_DUAL
				&cpu0_intc  0xffffffff &cpu0_intc  0xffffffff
				&cpu0_intc  0xffffffff &cpu0_intc  0xffffffff
				&cpu0_intc  0xffffffff &cpu0_intc  0xffffffff
				&cpu0_intc  0xffffffff &cpu0_intc  0xffffffff
				&cpu0_intc  0xffffffff &cpu0_intc  0xffffffff
				&cpu0_intc  0xffffffff &cpu0_intc  0xffffffff
				&cpu0_intc  0xffffffff &cpu0_intc  0xffffffff
				&cpu0_intc  0xffffffff &cpu0_intc  0xffffffff
				&cpu0_intc  0xffffffff
				&cpu0_intc  0xffffffff &cpu0_intc  0xffffffff
				&cpu0_intc  0xffffffff &cpu0_intc  0xffffffff
				&cpu0_intc  0xffffffff &cpu0_intc  0xffffffff
				&cpu0_intc  0xffffffff &cpu0_intc  0xffffffff
				&cpu0_intc  0xffffffff &cpu0_intc  0xffffffff
				&cpu0_intc  0xffffffff &cpu0_intc  0xffffffff
				&cpu0_intc  0xffffffff &cpu0_intc  0xffffffff
				&cpu0_intc  0xffffffff &cpu0_intc  0xffffffff
				&cpu0_intc  0xffffffff
#endif /* CONFIG_DUOWEN_PLIC_DUAL */
#endif /* CONFIG_DUOWEN_APC_4 */
#else /* CONFIG_SMP */
				&cpu0_intc  0xb        &cpu0_intc  0xffffffff
				&cpu0_intc  0xffffffff &cpu0_intc  0xffffffff
				&cpu0_intc  0xffffffff &cpu0_intc  0xffffffff
				&cpu0_intc  0xffffffff &cpu0_intc  0xffffffff
				&cpu0_intc  0xffffffff &cpu0_intc  0xffffffff
				&cpu0_intc  0xffffffff &cpu0_intc  0xffffffff
				&cpu0_intc  0xffffffff &cpu0_intc  0xffffffff
				&cpu0_intc  0xffffffff &cpu0_intc  0xffffffff
				&cpu0_intc  0xffffffff
				&cpu0_intc  0x9        &cpu0_intc  0xffffffff
				&cpu0_intc  0xffffffff &cpu0_intc  0xffffffff
				&cpu0_intc  0xffffffff &cpu0_intc  0xffffffff
				&cpu0_intc  0xffffffff &cpu0_intc  0xffffffff
				&cpu0_intc  0xffffffff &cpu0_intc  0xffffffff
				&cpu0_intc  0xffffffff &cpu0_intc  0xffffffff
				&cpu0_intc  0xffffffff &cpu0_intc  0xffffffff
				&cpu0_intc  0xffffffff &cpu0_intc  0xffffffff
				&cpu0_intc  0xffffffff
#endif /* CONFIG_SMP */
			>;
			interrupt-controller;
			compatible = "riscv,plic0";
#ifdef CONFIG_DUOWEN_PLIC_DUAL
			smarco,plic-irq-base = <0>;
			smarco,plic-ctx-base = <0>;
			smarco,plic-ctx-size = <34>;
#endif /* CONFIG_DUOWEN_PLIC_DUAL */
			#interrupt-cells = <0x1>;
			#address-cells = <0x0>;
		};

#ifdef CONFIG_DUOWEN_SBI_DUAL
		plic1: interrupt-controller@8ff70000000 {
			riscv,ndev = <255>;
			reg = <0x8ff 0x70000000 0x0 0x4000000>;
			interrupts-extended = <
#ifdef CONFIG_DUOWEN_APC_4
#ifdef CONFIG_DUOWEN_PLIC_DUAL
				&cpu0_intc  0xffffffff &cpu0_intc  0xffffffff
				&cpu0_intc  0xffffffff &cpu0_intc  0xffffffff
				&cpu0_intc  0xffffffff &cpu0_intc  0xffffffff
				&cpu0_intc  0xffffffff &cpu0_intc  0xffffffff
				&cpu0_intc  0xffffffff &cpu0_intc  0xffffffff
				&cpu0_intc  0xffffffff &cpu0_intc  0xffffffff
				&cpu0_intc  0xffffffff &cpu0_intc  0xffffffff
				&cpu0_intc  0xffffffff &cpu0_intc  0xffffffff
				&cpu0_intc  0xffffffff
				&cpu0_intc  0xffffffff &cpu0_intc  0xffffffff
				&cpu0_intc  0xffffffff &cpu0_intc  0xffffffff
				&cpu0_intc  0xffffffff &cpu0_intc  0xffffffff
				&cpu0_intc  0xffffffff &cpu0_intc  0xffffffff
				&cpu0_intc  0xffffffff &cpu0_intc  0xffffffff
				&cpu0_intc  0xffffffff &cpu0_intc  0xffffffff
				&cpu0_intc  0xffffffff &cpu0_intc  0xffffffff
				&cpu0_intc  0xffffffff &cpu0_intc  0xffffffff
				&cpu0_intc  0xffffffff
#endif /* CONFIG_DUOWEN_PLIC_DUAL */
				&cpu4_intc  0xb        &cpu5_intc  0xb
				&cpu6_intc  0xb        &cpu7_intc  0xb
				&cpu0_intc  0xffffffff &cpu0_intc  0xffffffff
				&cpu0_intc  0xffffffff &cpu0_intc  0xffffffff
				&cpu0_intc  0xffffffff &cpu0_intc  0xffffffff
				&cpu0_intc  0xffffffff &cpu0_intc  0xffffffff
				&cpu0_intc  0xffffffff &cpu0_intc  0xffffffff
				&cpu0_intc  0xffffffff &cpu0_intc  0xffffffff
				&cpu0_intc  0xffffffff
				&cpu4_intc  0x9        &cpu5_intc  0x9
				&cpu6_intc  0x9        &cpu7_intc  0x9
				&cpu0_intc  0xffffffff &cpu0_intc  0xffffffff
				&cpu0_intc  0xffffffff &cpu0_intc  0xffffffff
				&cpu0_intc  0xffffffff &cpu0_intc  0xffffffff
				&cpu0_intc  0xffffffff &cpu0_intc  0xffffffff
				&cpu0_intc  0xffffffff &cpu0_intc  0xffffffff
				&cpu0_intc  0xffffffff &cpu0_intc  0xffffffff
				&cpu0_intc  0xffffffff
#else /* CONFIG_DUOWEN_APC_4 */
#ifdef CONFIG_DUOWEN_PLIC_DUAL
				&cpu0_intc  0xffffffff &cpu0_intc  0xffffffff
				&cpu0_intc  0xffffffff &cpu0_intc  0xffffffff
				&cpu0_intc  0xffffffff &cpu0_intc  0xffffffff
				&cpu0_intc  0xffffffff &cpu0_intc  0xffffffff
				&cpu0_intc  0xffffffff &cpu0_intc  0xffffffff
				&cpu0_intc  0xffffffff &cpu0_intc  0xffffffff
				&cpu0_intc  0xffffffff &cpu0_intc  0xffffffff
				&cpu0_intc  0xffffffff &cpu0_intc  0xffffffff
				&cpu0_intc  0xffffffff
				&cpu0_intc  0xffffffff &cpu0_intc  0xffffffff
				&cpu0_intc  0xffffffff &cpu0_intc  0xffffffff
				&cpu0_intc  0xffffffff &cpu0_intc  0xffffffff
				&cpu0_intc  0xffffffff &cpu0_intc  0xffffffff
				&cpu0_intc  0xffffffff &cpu0_intc  0xffffffff
				&cpu0_intc  0xffffffff &cpu0_intc  0xffffffff
				&cpu0_intc  0xffffffff &cpu0_intc  0xffffffff
				&cpu0_intc  0xffffffff &cpu0_intc  0xffffffff
				&cpu0_intc  0xffffffff
#endif /* CONFIG_DUOWEN_PLIC_DUAL */
				&cpu16_intc 0xb        &cpu17_intc 0xb
				&cpu18_intc 0xb        &cpu19_intc 0xb
				&cpu20_intc 0xb        &cpu21_intc 0xb
				&cpu22_intc 0xb        &cpu23_intc 0xb
				&cpu24_intc 0xb        &cpu25_intc 0xb
				&cpu26_intc 0xb        &cpu27_intc 0xb
				&cpu28_intc 0xb        &cpu29_intc 0xb
				&cpu30_intc 0xb        &cpu31_intc 0xb
				&cpu0_intc  0xffffffff
				&cpu16_intc 0x9        &cpu17_intc 0x9
				&cpu18_intc 0x9        &cpu19_intc 0x9
				&cpu20_intc 0x9        &cpu21_intc 0x9
				&cpu22_intc 0x9        &cpu23_intc 0x9
				&cpu24_intc 0x9        &cpu25_intc 0x9
				&cpu26_intc 0x9        &cpu27_intc 0x9
				&cpu28_intc 0x9        &cpu29_intc 0x9
				&cpu30_intc 0x9        &cpu31_intc 0x9
				&cpu0_intc  0xffffffff
#endif /* CONFIG_DUOWEN_APC_4 */
			>;
			interrupt-controller;
			compatible = "riscv,plic0";
#ifdef CONFIG_DUOWEN_PLIC_DUAL
			smarco,plic-irq-base = <257>;
			smarco,plic-ctx-base = <34>;
			smarco,plic-ctx-size = <34>;
#endif /* CONFIG_DUOWEN_PLIC_DUAL */
			#interrupt-cells = <0x1>;
			#address-cells = <0x0>;
		};
#endif /* CONFIG_DUOWEN_SBI_DUAL */

		clint0: clint@ff010f0000 {
			interrupts-extended = <
#ifdef CONFIG_SMP
#ifdef CONFIG_DUOWEN_APC_4
				&cpu0_intc  0x3        &cpu0_intc  0x7
				&cpu1_intc  0x3        &cpu1_intc  0x7
				&cpu2_intc  0x3        &cpu2_intc  0x7
				&cpu3_intc  0x3        &cpu3_intc  0x7
				&cpu0_intc  0xffffffff &cpu0_intc  0xffffffff
				&cpu0_intc  0xffffffff &cpu0_intc  0xffffffff
				&cpu0_intc  0xffffffff &cpu0_intc  0xffffffff
				&cpu0_intc  0xffffffff &cpu0_intc  0xffffffff
				&cpu0_intc  0xffffffff &cpu0_intc  0xffffffff
				&cpu0_intc  0xffffffff &cpu0_intc  0xffffffff
				&cpu0_intc  0xffffffff &cpu0_intc  0xffffffff
				&cpu0_intc  0xffffffff &cpu0_intc  0xffffffff
				&cpu0_intc  0xffffffff &cpu0_intc  0xffffffff
				&cpu0_intc  0xffffffff &cpu0_intc  0xffffffff
				&cpu0_intc  0xffffffff &cpu0_intc  0xffffffff
				&cpu0_intc  0xffffffff &cpu0_intc  0xffffffff
#ifdef CONFIG_DUOWEN_SBI_DUAL
				&cpu4_intc  0x3        &cpu4_intc  0x7
				&cpu5_intc  0x3        &cpu5_intc  0x7
				&cpu6_intc  0x3        &cpu6_intc  0x7
				&cpu7_intc  0x3        &cpu7_intc  0x7
#endif /* CONFIG_DUOWEN_SBI_DUAL */
#else /* CONFIG_DUOWEN_APC_4 */
				&cpu0_intc  0x3        &cpu0_intc  0x7
				&cpu1_intc  0x3        &cpu1_intc  0x7
				&cpu2_intc  0x3        &cpu2_intc  0x7
				&cpu3_intc  0x3        &cpu3_intc  0x7
				&cpu4_intc  0x3        &cpu4_intc  0x7
				&cpu5_intc  0x3        &cpu5_intc  0x7
				&cpu6_intc  0x3        &cpu6_intc  0x7
				&cpu7_intc  0x3        &cpu7_intc  0x7
				&cpu8_intc  0x3        &cpu8_intc  0x7
				&cpu9_intc  0x3        &cpu9_intc  0x7
				&cpu10_intc 0x3        &cpu10_intc 0x7
				&cpu11_intc 0x3        &cpu11_intc 0x7
				&cpu12_intc 0x3        &cpu12_intc 0x7
				&cpu13_intc 0x3        &cpu13_intc 0x7
				&cpu14_intc 0x3        &cpu14_intc 0x7
				&cpu15_intc 0x3        &cpu15_intc 0x7
#ifdef CONFIG_DUOWEN_SBI_DUAL
				&cpu16_intc 0x3        &cpu16_intc 0x7
				&cpu17_intc 0x3        &cpu17_intc 0x7
				&cpu18_intc 0x3        &cpu18_intc 0x7
				&cpu19_intc 0x3        &cpu19_intc 0x7
				&cpu20_intc 0x3        &cpu20_intc 0x7
				&cpu21_intc 0x3        &cpu21_intc 0x7
				&cpu22_intc 0x3        &cpu22_intc 0x7
				&cpu23_intc 0x3        &cpu23_intc 0x7
				&cpu24_intc 0x3        &cpu24_intc 0x7
				&cpu25_intc 0x3        &cpu25_intc 0x7
				&cpu26_intc 0x3        &cpu26_intc 0x7
				&cpu27_intc 0x3        &cpu27_intc 0x7
				&cpu28_intc 0x3        &cpu28_intc 0x7
				&cpu29_intc 0x3        &cpu29_intc 0x7
				&cpu30_intc 0x3        &cpu30_intc 0x7
				&cpu31_intc 0x3        &cpu31_intc 0x7
#endif /* CONFIG_DUOWEN_SBI_DUAL */
#endif /* CONFIG_DUOWEN_APC_4 */
#else /* CONFIG_SMP */
				&cpu0_intc  0x3        &cpu0_intc  0x7
#endif /* CONFIG_SMP */
			>;
			reg = <0xff 0x10f0000 0x0 0x10000>;
			compatible = "riscv,clint0";
		};
#endif /* CONFIG_DUOWEN_APC */

#ifdef CONFIG_DUOWEN_IMC
		plic0: interrupt-controller@ff70000000 {
			riscv,ndev = <255>;
			reg = <0xff 0x70000000 0x0 0x4000000>;
			interrupts-extended = <
				&cpu0_intc  0xffffffff &cpu0_intc  0xffffffff
				&cpu0_intc  0xffffffff &cpu0_intc  0xffffffff
				&cpu0_intc  0xffffffff &cpu0_intc  0xffffffff
				&cpu0_intc  0xffffffff &cpu0_intc  0xffffffff
				&cpu0_intc  0xffffffff &cpu0_intc  0xffffffff
				&cpu0_intc  0xffffffff &cpu0_intc  0xffffffff
				&cpu0_intc  0xffffffff &cpu0_intc  0xffffffff
				&cpu0_intc  0xffffffff &cpu0_intc  0xffffffff
				&cpu0_intc  0xb
				&cpu0_intc  0xffffffff &cpu0_intc  0xffffffff
				&cpu0_intc  0xffffffff &cpu0_intc  0xffffffff
				&cpu0_intc  0xffffffff &cpu0_intc  0xffffffff
				&cpu0_intc  0xffffffff &cpu0_intc  0xffffffff
				&cpu0_intc  0xffffffff &cpu0_intc  0xffffffff
				&cpu0_intc  0xffffffff &cpu0_intc  0xffffffff
				&cpu0_intc  0xffffffff &cpu0_intc  0xffffffff
				&cpu0_intc  0xffffffff &cpu0_intc  0xffffffff
				&cpu0_intc  0x9
			>;
			interrupt-controller;
			compatible = "riscv,plic0";
			smarco,plic-irq-base = <0>;
			smarco,plic-ctx-base = <0>;
			smarco,plic-ctx-size = <34>;
			#interrupt-cells = <0x1>;
			#address-cells = <0x0>;
		};
		timer3: rvtimer@ff66300000 {
			interrupts-extended = <&cpu0_intc  0x7>;
			reg = <0xff 0x66300000 0x0 0x400>;
			smarco,rvtimer-cmp-off = <0x208>;
			smarco,rvtimer-val-off = <0x40>;
			compatible = "smarco,rvtimer0";
		};
#endif /* CONFIG_DUOWEN_IMC */

		crcntl: crcntl-clock@ff60000000 {
			compatible = "smarco,duowen-crcntl";
			reg = <0xff 0x60000000 0x0 0x1000>;
			/* reg = <0x8ff 0x60000000 0x0 0x1000>; */
			#clock-cells = <1>;
		};

#ifdef CONFIG_DUOWEN_ETH_DTS
		stmmac_axi_setup: stmmac-axi-config {
			snps,wr_osr_lmt = <0x3f>;
			snps,rd_osr_lmt = <0x3f>;
			snps,blen = <0 0 0 32 16 8 4>;
		};
		mtl_rx_setup: rx-queues-config {
			snps,rx-queues-to-use = <1>;
			snps,rx-sched-sp;
			queue0 {
				snps,dcb-algorithm;
				snps,map-to-dma-channel = <0x0>;
				snps,priority = <0x0>;
			};
		};
		mtl_tx_setup: tx-queues-config {
			snps,tx-queues-to-use = <2>;
			snps,tx-sched-wrr;
			queue0 {
				snps,weight = <0x10>;
				snps,dcb-algorithm;
				snps,priority = <0x0>;
			};
			queue1 {
				snps,avb-algorithm;
				snps,send_slope = <0x1000>;
				snps,idle_slope = <0x1000>;
				snps,high_credit = <0x3e800>;
				snps,low_credit = <0xffc18000>;
				snps,priority = <0x1>;
			};
		};
		xgmac0: ethernet@ff6a000000 {
#ifdef CONFIG_DUOWEN_ETH_GENERIC
			compatible = "snps,dwxgmac-2.20", "snps,dwxgmac";
#else /* CONFIG_DUOWEN_ETH_GENERIC */
			compatible = "smarco,duowen-xgmac2", "snps,dwxgmac";
#endif /* CONFIG_DUOWEN_ETH_GENERIC */
			reg = <0xff 0x6a000000 0x0 0x100000>;
			interrupt-parent = <&plic0>;
			interrupts = <196 195 194>;
			interrupt-names = "macirq", "eth_wake_irq", "eth_lpi";
			mac-address = [c69ded9a297c];
			max-frame-size = <3800>;
#ifdef CONFIG_DUOWEN_ETH_10000BASE_KX4
			phy-mode = "usxgmii";
#endif /* CONFIG_DUOWEN_ETH_10000BASE_KX4 */
#ifdef CONFIG_DUOWEN_ETH_10000BASE_KR
			phy-mode = "10gbase-kr";
#endif /* CONFIG_DUOWEN_ETH_10000BASE_KR */
			snps,multicast-filter-bins = <256>;
			snps,perfect-filter-entries = <128>;
			rx-fifo-depth = <16384>;
			tx-fifo-depth = <16384>;
			clocks = <&crcntl sbi_sysfab_clk>,
			         <&crcntl sbi_sgmii_ref_clk>;
			clock-names = "stmmaceth", "ptp_ref";
			snps,axi-config = <&stmmac_axi_setup>;
			snps,mtl-rx-config = <&mtl_rx_setup>;
			snps,mtl-tx-config = <&mtl_tx_setup>;
			/* MDIO is used for external phy configuration.
			 * The internal phy uses apb slave interface.
			 * Default to the internal phy.
			 */
			mdio0 {
				#address-cells = <1>;
				#size-cells = <0>;
				compatible = "snps,dwmac-mdio";
#ifndef CONFIG_DUOWEN_ETH_GENERIC
				smarco,has_xpcs;
				smarco,probe_phy;
#endif /* CONFIG_DUOWEN_ETH_GENERIC */
				ethernet-phy@0 {
					reg = <0>;
				};
			};
#ifdef CONFIG_DUOWEN_ETH_MAC2MAC
			fixed-link {
				speed = <10000>;
				full-duplex;
			};
#endif /* CONFIG_DUOWEN_ETH_MAC2MAC */
		};
#endif /* CONFIG_DUOWEN_ETH_DTS */

#ifdef CONFIG_DUOWEN_SMMU_DTS
		/* DMA SMMU */
		dma_smmu: iommu@ff08000000 {
			compatible = "smarco,riscv-smmu";
			reg = <0xff 0x8000000 0x0 0x20000>;
			interrupt-parent = <&plic0>;
			interrupts = <83>;
			interrupt-names = "combined";
			dma_coherent;
			#iommu-cells = <1>;
		};

		/* PCIe SMMU */
		pcie_smmu: iommu@ff08400000 {
			compatible = "smarco,riscv-smmu";
			reg = <0xff 0x8400000 0x0 0x20000>;
			interrupt-parent = <&plic0>;
			interrupts = <80>;
			interrupt-names = "combined";
			dma_coherent;
			#iommu-cells = <1>;
		};
#endif /* CONFIG_DUOWEN_SMMU_DTS */

#ifdef CONFIG_DUOWEN_PCIE_DTS
		pcie@ff09100000 {
			compatible = "smarco,duowen-pcie";
			reg = < 0xff 0x9100000 0x00 0x80000 0x400 0xe0000000 0x00 0x2000000 >;
			reg-names = "dbi\0config";
			#address-cells = < 0x03 >;
			#size-cells = < 0x02 >;
			device_type = "pci";
			ranges = < 0x83000000 0x00 0x00 0x400 0x00 0x00 0xe0000000 0x81000000 0x01 0x00 0x401 0x00 0x00 0x100000 >;
			interrupts-extended = < &plic0 0x08 &plic0 0x03 >;
			atu_offset = < 0x40000 >;
			ctrl_base = < 0x400 0x0 >;
			num-viewport = < 0x0 >;
			num-lanes = < 0x8 >;
			max-link-speed = <4>;
		};

		pcie@ff09200000 {
			compatible = "smarco,duowen-pcie";
			reg = < 0xff 0x9200000 0x00 0x80000 0x480 0xe0000000 0x00 0x2000000 >;
			reg-names = "dbi\0config";
			#address-cells = < 0x03 >;
			#size-cells = < 0x02 >;
			device_type = "pci";
			ranges = < 0x83000000 0x00 0x00 0x480 0x00 0x00 0xe0000000 0x81000000 0x01 0x00 0x481 0x00 0x00 0x100000 >;
			interrupts-extended = < &plic0 0x13 &plic0 0xe >;
			atu_offset = < 0x40000 >;
			ctrl_base = < 0x480 0x0 >;
			num-viewport = < 0x0 >;
			num-lanes = < 0x8 >;
			max-link-speed = <4>;
			/* status = "disabled"; */
		};
#endif /* CONFIG_DUOWEN_PCIE_DTS */

#ifdef CONFIG_DUOWEN_DMAC_DTS
		dma:dma@ff03000000 {
			compatible = "snps,axi-dma-1.01a";
			reg = < 0xff 0x3000000 0x0 0x100000 >;
			clocks = <&crcntl sbi_dma_clk>,
				 <&crcntl sbi_sysfab_clk>;
			clock-names = "core-clk", "cfgr-clk";
			interrupt-parent = <&plic0>;
			interrupts = <65>;
			interrupts-names = "dma";
			dma-channels = <8>;
			snps,dma-masters = <1>;
			snps,data-width = <5>;
			snps,block-size = <0x200000 0x200000 0x200000 0x200000 0x200000 0x200000 0x200000 0x200000>;
			snps,priority = <0 1 2 3 4 5 6 7>;
			snps,axi-max-burst-len = <16>;
			#dma-cells = <1>;
			status = "okay";
		};

#ifdef CONFIG_DUOWEN_SBI_DUAL
		dma1:dma@8ff03000000 {
			compatible = "snps,axi-dma-1.01a";
			reg = < 0x8ff 0x3000000 0x0 0x100000 >;
			clocks = <&crcntl sbi_dma_clk>,
				 <&crcntl sbi_sysfab_clk>;
			clock-names = "core-clk", "cfgr-clk";
			interrupt-parent = <&plic1>;
			interrupts = <65>;
			interrupts-names = "dma1";
			dma-channels = <8>;
			snps,dma-masters = <1>;
			snps,data-width = <5>;
			snps,block-size = <0x200000 0x200000 0x200000 0x200000 0x200000 0x200000 0x200000 0x200000>;
			snps,priority = <0 1 2 3 4 5 6 7>;
			snps,axi-max-burst-len = <16>;
			#dma-cells = <1>;
			status = "okay";
		};
#endif /* CONFIG_DUOWEN_SBI_DUAL */
#endif /* CONFIG_DUOWEN_DMAC_DTS */
	};
};
